# ESP32-P4 register map
Vendor: ESPRESSIF SYSTEMS (SHANGHAI) CO., LTD.; Series: ESP32 P-Series; File version: 2
CPU: RV32IMAFC r0p0, little endian, no MPU, FPU, 0 interrupt priority bits
Address unit: 32 bits
Registers are 32-bit, read-write, reset 0x0 unless marked. A register's access mark holds for its fields unless they carry their own. Offsets are from the block's base; [hi:lo] are bit positions; {n}, {i} and the like mark numbered series.

## I3C_MST — I3C Controller (Master)
Base 0x500DA000
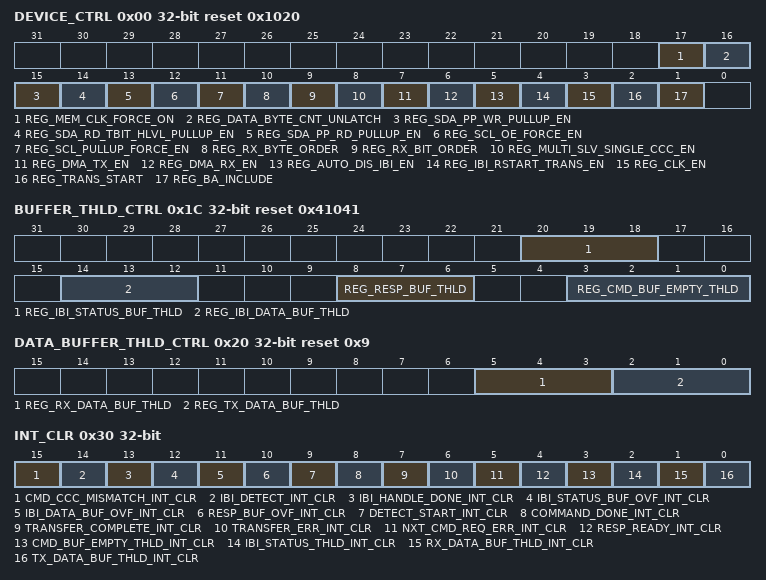
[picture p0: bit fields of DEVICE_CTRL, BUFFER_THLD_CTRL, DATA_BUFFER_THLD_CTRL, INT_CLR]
0x00 DEVICE_CTRL reset 0x1020 — DEVICE_CTRL register controls the transfer properties and disposition of controllers capabilities.
  [17] REG_MEM_CLK_FORCE_ON — 1: dev characteristic and address table memory clk date force on . 0 : clock gating by rd/wr.
  [16] REG_DATA_BYTE_CNT_UNLATCH — 1: read current real-time updated value 0: read latch data byte cnt value
  [15] REG_SDA_PP_WR_PULLUP_EN
  [14] REG_SDA_RD_TBIT_HLVL_PULLUP_EN
  [13] REG_SDA_PP_RD_PULLUP_EN
  [12] REG_SCL_OE_FORCE_EN — This bit is used to force scl_oe
  [11] REG_SCL_PULLUP_FORCE_EN — This bit is used to force scl_pullup_en
  [10] REG_RX_BYTE_ORDER
  [9] REG_RX_BIT_ORDER — 0: rx low byte fist, 1: rx high byte first
  [8] REG_MULTI_SLV_SINGLE_CCC_EN — 0: rx high bit first, 1: rx low bit first
  [7] REG_DMA_TX_EN
  [6] REG_DMA_RX_EN
  [5] REG_AUTO_DIS_IBI_EN
  [4] REG_IBI_RSTART_TRANS_EN
  [3] REG_CLK_EN
  [2] REG_TRANS_START — Transfer Start
  [1] REG_BA_INCLUDE — This bit is used to include I3C broadcast address(0x7E) for private transfer.(If I3C broadcast address is not include for the private transfer, In-Band Interrupts driven from Slaves may not win address arbitration. Hence IBIs will get delayed)
0x1C BUFFER_THLD_CTRL reset 0x41041 — In-Band Interrupt Status Threshold Value . Every In Band Interrupt received by I3C controller generates an IBI status. This field controls the number of IBI status entries in the IBI buffer that trigger the IBI_STATUS_THLD_STAT interrupt.
  [20:18] REG_IBI_STATUS_BUF_THLD
  [14:12] REG_IBI_DATA_BUF_THLD — In-Band Interrupt Data Threshold Value . Every In Band Interrupt received by I3C controller generates an IBI status. This field controls the number of IBI data entries in the IBI buffer that trigger the IBI_DATA_THLD_STAT interrupt.
  [8:6] REG_RESP_BUF_THLD — Response Buffer Threshold Value is used to control the number of entries in the Response Buffer that trigger the RESP_READY_STAT_INTR.
  [3:0] REG_CMD_BUF_EMPTY_THLD — Command Buffer Empty Threshold Value is used to control the number of empty locations(or greater) in the Command Buffer that trigger CMD_BUFFER_READY_STAT interrupt.
0x20 DATA_BUFFER_THLD_CTRL reset 0x9
  [5:3] REG_RX_DATA_BUF_THLD — Receive Buffer Threshold Value. This field controls the number of empty locations in the Receive FIFO that trigger the RX_THLD_STAT interrupt. Supports: 000:2 001:4 010:8 011:16 100:31, else:31
  [2:0] REG_TX_DATA_BUF_THLD — Transmit Buffer Threshold Value. This field controls the number of empty locations in the Transmit FIFO that trigger the TX_THLD_STAT interrupt. Supports values: 000:2 001:4 010:8 011:16 100:31, else:31
0x24 IBI_NOTIFY_CTRL
  [2] REG_NOTIFY_SIR_REJECTED — Notify Rejected Slave Interrupt Request Control. This bit is used to suppress reporting to the application about Slave Interrupt Request. 0:Suppress passing the IBI Status to the IBI FIFO(hence not notifying the application) when a SIR request is NACKed and auto-disabled base on the IBI_SIR_REQ_REJECT register. 1: Writes IBI Status to the IBI FIFO(hence notifying the application) when SIR request is NACKed and auto-disabled based on the IBI_SIR_REQ_REJECT registerl.
0x28 IBI_SIR_REQ_PAYLOAD
  [31:0] REG_SIR_REQ_PAYLOAD
0x2C IBI_SIR_REQ_REJECT
  [31:0] REG_SIR_REQ_REJECT — The application of controller can decide whether to send ACK or NACK for Slave request received from any I3C device. A device specific response control bit is provided to select the response option, Master will ACK/NACK the Master Request based on programming of control bit, corresponding to the interrupting device. 0:ACK the SIR Request 1:NACK and send direct auto disable CCC
0x30 INT_CLR wo
  [15] CMD_CCC_MISMATCH_INT_CLR, [14] IBI_DETECT_INT_CLR, [13] IBI_HANDLE_DONE_INT_CLR, [12] IBI_STATUS_BUF_OVF_INT_CLR, [11] IBI_DATA_BUF_OVF_INT_CLR, [10] RESP_BUF_OVF_INT_CLR, [9] DETECT_START_INT_CLR, [8] COMMAND_DONE_INT_CLR, [7] TRANSFER_COMPLETE_INT_CLR, [6] TRANSFER_ERR_INT_CLR, [5] NXT_CMD_REQ_ERR_INT_CLR, [4] RESP_READY_INT_CLR, [3] CMD_BUF_EMPTY_THLD_INT_CLR, [2] IBI_STATUS_THLD_INT_CLR, [1] RX_DATA_BUF_THLD_INT_CLR, [0] TX_DATA_BUF_THLD_INT_CLR
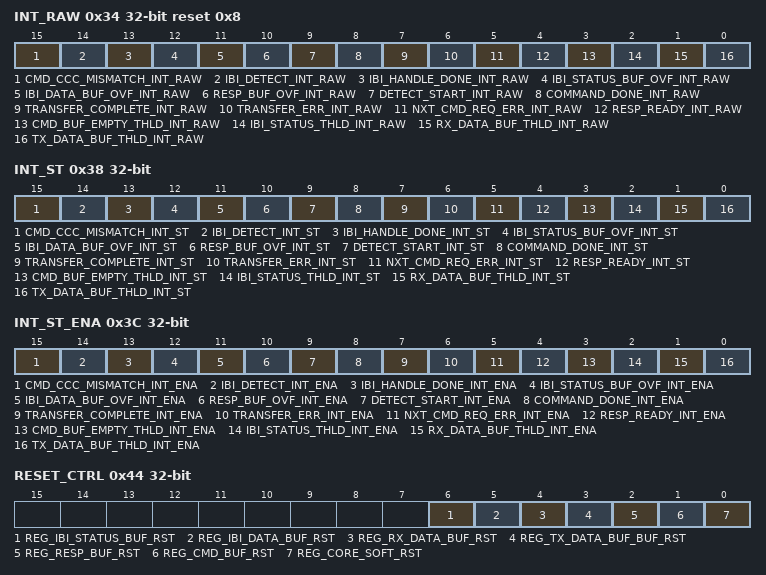
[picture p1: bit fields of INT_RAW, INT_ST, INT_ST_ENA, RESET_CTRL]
0x34 INT_RAW reset 0x8
  [15] CMD_CCC_MISMATCH_INT_RAW, [14] IBI_DETECT_INT_RAW, [13] IBI_HANDLE_DONE_INT_RAW, [12] IBI_STATUS_BUF_OVF_INT_RAW, [11] IBI_DATA_BUF_OVF_INT_RAW, [10] RESP_BUF_OVF_INT_RAW, [9] DETECT_START_INT_RAW, [8] COMMAND_DONE_INT_RAW, [7] TRANSFER_COMPLETE_INT_RAW, [6] TRANSFER_ERR_INT_RAW, [5] NXT_CMD_REQ_ERR_INT_RAW, [4] RESP_READY_INT_RAW, [3] CMD_BUF_EMPTY_THLD_INT_RAW, [2] IBI_STATUS_THLD_INT_RAW, [1] RX_DATA_BUF_THLD_INT_RAW, [0] TX_DATA_BUF_THLD_INT_RAW
0x38 INT_ST ro
  [15] CMD_CCC_MISMATCH_INT_ST
  [14] IBI_DETECT_INT_ST
  [13] IBI_HANDLE_DONE_INT_ST
  [12] IBI_STATUS_BUF_OVF_INT_ST
  [11] IBI_DATA_BUF_OVF_INT_ST
  [10] RESP_BUF_OVF_INT_ST
  [9] DETECT_START_INT_ST
  [8] COMMAND_DONE_INT_ST
  [7] TRANSFER_COMPLETE_INT_ST
  [6] TRANSFER_ERR_INT_ST — This interrupt is generated if any error occurs during transfer. The error type will be specified in the response packet associated with the command (in ERR_STATUS field of RESPONSE_BUFFER_PORT register). This bit can be cleared by writing 1'h1.
  [5] NXT_CMD_REQ_ERR_INT_ST — This interrupt is generated if toc is 0(master will restart next command), but command buf is empty.
  [4] RESP_READY_INT_ST — This interrupt is generated when number of entries in response buffer is greater than or equal to threshold value specified by RESP_BUF_THLD field in BUFFER_THLD_CTRL register. This interrupt will be cleared automatically when number of entries in response buffer is less than threshold value.
  [3] CMD_BUF_EMPTY_THLD_INT_ST — This interrupt is generated when number of empty locations in command buffer is greater than or equal to threshold value specified by CMD_EMPTY_BUF_THLD field in BUFFER_THLD_CTRL register. This interrupt will be cleared automatically when number of empty locations in command buffer is less than threshold value.
  [2] IBI_STATUS_THLD_INT_ST — Only used in master mode. This interrupt is generated when number of entries in IBI buffer is greater than or equal to threshold value specified by IBI_BUF_THLD field in BUFFER_THLD_CTRL register. This interrupt will be cleared automatically when number of entries in IBI buffer is less than threshold value.
  [1] RX_DATA_BUF_THLD_INT_ST — This interrupt is generated when number of entries in receive buffer is greater than or equal to threshold value specified by RX_BUF_THLD field in DATA_BUFFER_THLD_CTRL register. This interrupt will be cleared automatically when number of entries in receive buffer is less than threshold value.
  [0] TX_DATA_BUF_THLD_INT_ST — This interrupt is generated when number of empty locations in transmit buffer is greater than or equal to threshold value specified by TX_EMPTY_BUS_THLD field in DATA_BUFFER_THLD_CTRL register. This interrupt will be cleared automatically when number of empty locations in transmit buffer is less than threshold value.
0x3C INT_ST_ENA — The Interrupt status will be updated in INTR_STATUS register if corresponding Status Enable bit set.
  [15] CMD_CCC_MISMATCH_INT_ENA
  [14] IBI_DETECT_INT_ENA
  [13] IBI_HANDLE_DONE_INT_ENA
  [12] IBI_STATUS_BUF_OVF_INT_ENA
  [11] IBI_DATA_BUF_OVF_INT_ENA
  [10] RESP_BUF_OVF_INT_ENA
  [9] DETECT_START_INT_ENA
  [8] COMMAND_DONE_INT_ENA
  [7] TRANSFER_COMPLETE_INT_ENA
  [6] TRANSFER_ERR_INT_ENA — Transfer error status enable
  [5] NXT_CMD_REQ_ERR_INT_ENA — next command request error status enable
  [4] RESP_READY_INT_ENA — Response buffer ready status enable.
  [3] CMD_BUF_EMPTY_THLD_INT_ENA — Command buffer ready status enable.
  [2] IBI_STATUS_THLD_INT_ENA — Only used in master mode. IBI Buffer threshold status enable.
  [1] RX_DATA_BUF_THLD_INT_ENA — Receive Buffer threshold status enable.
  [0] TX_DATA_BUF_THLD_INT_ENA — Transmit Buffer threshold status enable.
0x44 RESET_CTRL access per field
  [6] REG_IBI_STATUS_BUF_RST rw, [5] REG_IBI_DATA_BUF_RST rw, [4] REG_RX_DATA_BUF_RST rw, [3] REG_TX_DATA_BUF_BUF_RST rw, [2] REG_RESP_BUF_RST rw, [1] REG_CMD_BUF_RST rw, [0] REG_CORE_SOFT_RST wo
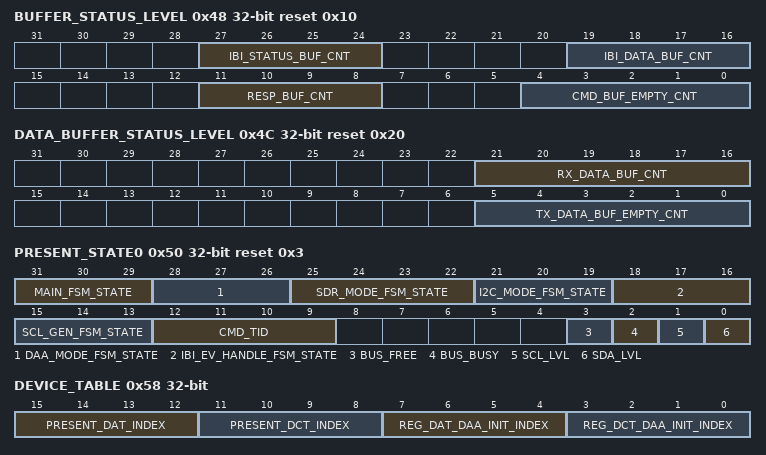
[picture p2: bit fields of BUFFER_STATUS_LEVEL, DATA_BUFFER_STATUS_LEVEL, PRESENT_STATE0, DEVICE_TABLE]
0x48 BUFFER_STATUS_LEVEL ro reset 0x10 — BUFFER_STATUS_LEVEL reflects the status level of Buffers in the controller.
  [27:24] IBI_STATUS_BUF_CNT — IBI Buffer Status Count contains the number of IBI status entries in the IBI Buffer. This field is used in master mode.
  [19:16] IBI_DATA_BUF_CNT — IBI Buffer Level Value contains the number of valid entries in the IBI Buffer. This is field is used in master mode.
  [11:8] RESP_BUF_CNT — Response Buffer Level Value contains the number of valid data entries in the response buffer.
  [4:0] CMD_BUF_EMPTY_CNT — Command Buffer Empty Locations contains the number of empty locations in the command buffer.
0x4C DATA_BUFFER_STATUS_LEVEL ro reset 0x20 — DATA_BUFFER_STATUS_LEVEL reflects the status level of the Buffers in the controller.
  [21:16] RX_DATA_BUF_CNT — Receive Buffer Level value contains the number of valid data entries in the receive buffer.
  [5:0] TX_DATA_BUF_EMPTY_CNT — Transmit Buffer Empty Level Value contains the number of empty locations in the transmit Buffer.
0x50 PRESENT_STATE0 ro reset 0x3
  [31:29] MAIN_FSM_STATE
  [28:26] DAA_MODE_FSM_STATE — Reflects whether the Master Controller is in IDLE or not. This bit will be set when all the buffer(Command, Response, IBI, Transmit, Receive) are empty along with the Master State machine is in idle state. 0X0: not in idle 0x1: in idle
  [25:22] SDR_MODE_FSM_STATE
  [21:19] I2C_MODE_FSM_STATE
  [18:16] IBI_EV_HANDLE_FSM_STATE
  [15:13] SCL_GEN_FSM_STATE
  [12:9] CMD_TID
  [3] BUS_FREE
  [2] BUS_BUSY
  [1] SCL_LVL — This bit is used to check the SDA line level to recover from error and for debugging. This bit reflects the value of synchronized sda_in_a.
  [0] SDA_LVL — This bit is used to check the SCL line level to recover from error and for debugging. This bit reflects the value of synchronized scl_in_a.
0x54 PRESENT_STATE1 ro
  [15:0] DATA_BYTE_CNT — Present transfer data byte cnt: tx data byte cnt if write rx data byte cnt if read ibi data byte cnt if IBI handle.
0x58 DEVICE_TABLE access per field — Pointer for Device Address Table
  [15:12] PRESENT_DAT_INDEX ro
  [11:8] PRESENT_DCT_INDEX ro
  [7:4] REG_DAT_DAA_INIT_INDEX rw
  [3:0] REG_DCT_DAA_INIT_INDEX rw — Reserved
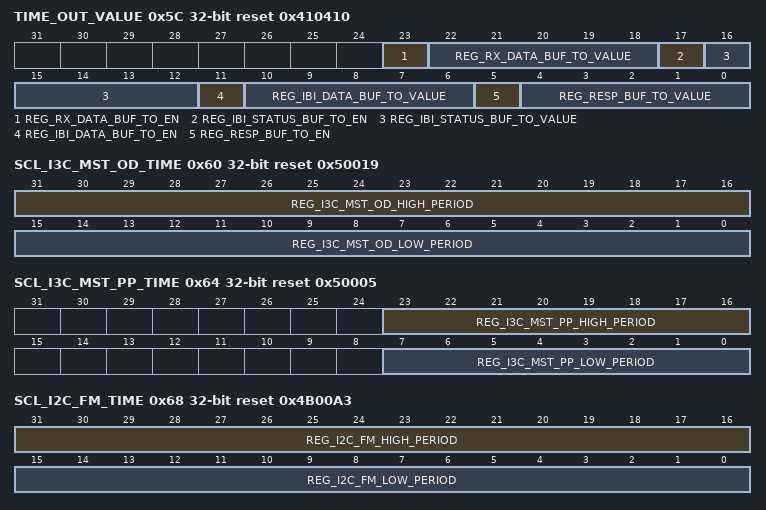
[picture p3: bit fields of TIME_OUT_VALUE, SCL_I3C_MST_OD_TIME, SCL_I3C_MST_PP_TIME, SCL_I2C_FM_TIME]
0x5C TIME_OUT_VALUE reset 0x410410
  [23] REG_RX_DATA_BUF_TO_EN, [22:18] REG_RX_DATA_BUF_TO_VALUE, [17] REG_IBI_STATUS_BUF_TO_EN, [16:12] REG_IBI_STATUS_BUF_TO_VALUE, [11] REG_IBI_DATA_BUF_TO_EN, [10:6] REG_IBI_DATA_BUF_TO_VALUE, [5] REG_RESP_BUF_TO_EN, [4:0] REG_RESP_BUF_TO_VALUE
0x60 SCL_I3C_MST_OD_TIME reset 0x50019
  [31:16] REG_I3C_MST_OD_HIGH_PERIOD — SCL Open-Drain High count for I3C transfers targeted to I3C devices.
  [15:0] REG_I3C_MST_OD_LOW_PERIOD — SCL Open-Drain low count for I3C transfers targeted to I3C devices.
0x64 SCL_I3C_MST_PP_TIME reset 0x50005
  [23:16] REG_I3C_MST_PP_HIGH_PERIOD, [7:0] REG_I3C_MST_PP_LOW_PERIOD
0x68 SCL_I2C_FM_TIME reset 0x4B00A3
  [31:16] REG_I2C_FM_HIGH_PERIOD — The SCL open-drain low count timing for I2C Fast Mode transfers.
  [15:0] REG_I2C_FM_LOW_PERIOD
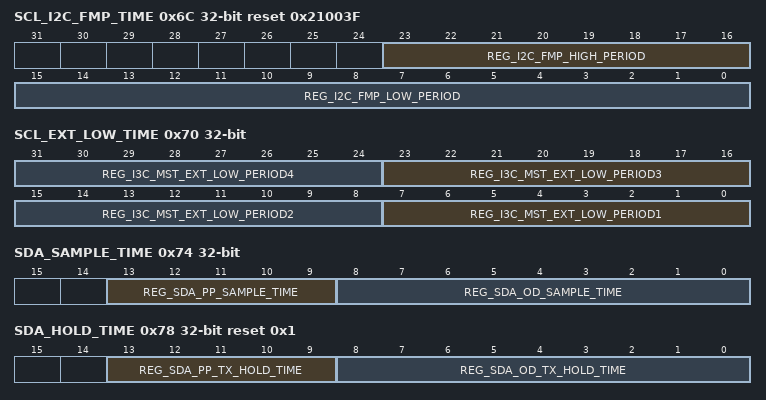
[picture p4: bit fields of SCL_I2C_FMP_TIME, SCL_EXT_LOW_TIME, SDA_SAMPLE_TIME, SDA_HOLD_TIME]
0x6C SCL_I2C_FMP_TIME reset 0x21003F
  [23:16] REG_I2C_FMP_HIGH_PERIOD, [15:0] REG_I2C_FMP_LOW_PERIOD
0x70 SCL_EXT_LOW_TIME
  [8n-1:8n-8] REG_I3C_MST_EXT_LOW_PERIOD{n} (n=1..4)
0x74 SDA_SAMPLE_TIME
  [13:9] REG_SDA_PP_SAMPLE_TIME — It is used to adjust sda sample point when scl high under push pull speed
  [8:0] REG_SDA_OD_SAMPLE_TIME — It is used to adjust sda sample point when scl high under open drain speed
0x78 SDA_HOLD_TIME reset 0x1
  [13:9] REG_SDA_PP_TX_HOLD_TIME — It is used to adjust sda dirve point after scl neg under push pull speed
  [8:0] REG_SDA_OD_TX_HOLD_TIME — It is used to adjust sda drive point after scl neg under open drain speed
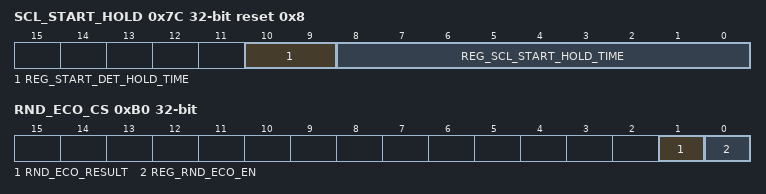
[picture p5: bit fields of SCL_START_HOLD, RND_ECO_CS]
0x7C SCL_START_HOLD reset 0x8
  [10:9] REG_START_DET_HOLD_TIME
  [8:0] REG_SCL_START_HOLD_TIME — I2C_SCL_START_HOLD_TIME
0x80 SCL_RSTART_SETUP reset 0x8
  [8:0] REG_SCL_RSTART_SETUP_TIME — I2C_SCL_RSTART_SETUP_TIME
0x84 SCL_STOP_HOLD reset 0x8
  [8:0] REG_SCL_STOP_HOLD_TIME — I2C_SCL_STOP_HOLD_TIME
0x88 SCL_STOP_SETUP reset 0x8
  [8:0] REG_SCL_STOP_SETUP_TIME — I2C_SCL_STOP_SETUP_TIME
0x90 BUS_FREE_TIME reset 0x5
  [15:0] REG_BUS_FREE_TIME — I3C Bus Free Count Value. This field is used only in Master mode. In pure Bus System, this field represents tCAS. In Mixed Bus System, this field is expected to be programmed to tLOW of I2C Timing.
0x94 SCL_TERMN_T_EXT_LOW_TIME reset 0x2
  [7:0] REG_I3C_MST_TERMN_T_EXT_LOW_TIME
0xA0 VER_ID reset 0x20230504
  [31:0] REG_I3C_MST_VER_ID — This field indicates the controller current release number that is read by an application.
0xA4 VER_TYPE
  [31:0] REG_I3C_MST_VER_TYPE — This field indicates the controller current release type that is read by an application.
0xAC FPGA_DEBUG_PROBE reset 0x1
  [31:0] REG_I3C_MST_FPGA_DEBUG_PROBE — For Debug Probe Test on FPGA
0xB0 RND_ECO_CS access per field
  [1] RND_ECO_RESULT ro, [0] REG_RND_ECO_EN rw
0xB4 RND_ECO_LOW
  [31:0] REG_RND_ECO_LOW
0xB8 RND_ECO_HIGH reset 0xFFFF
  [31:0] REG_RND_ECO_HIGH
